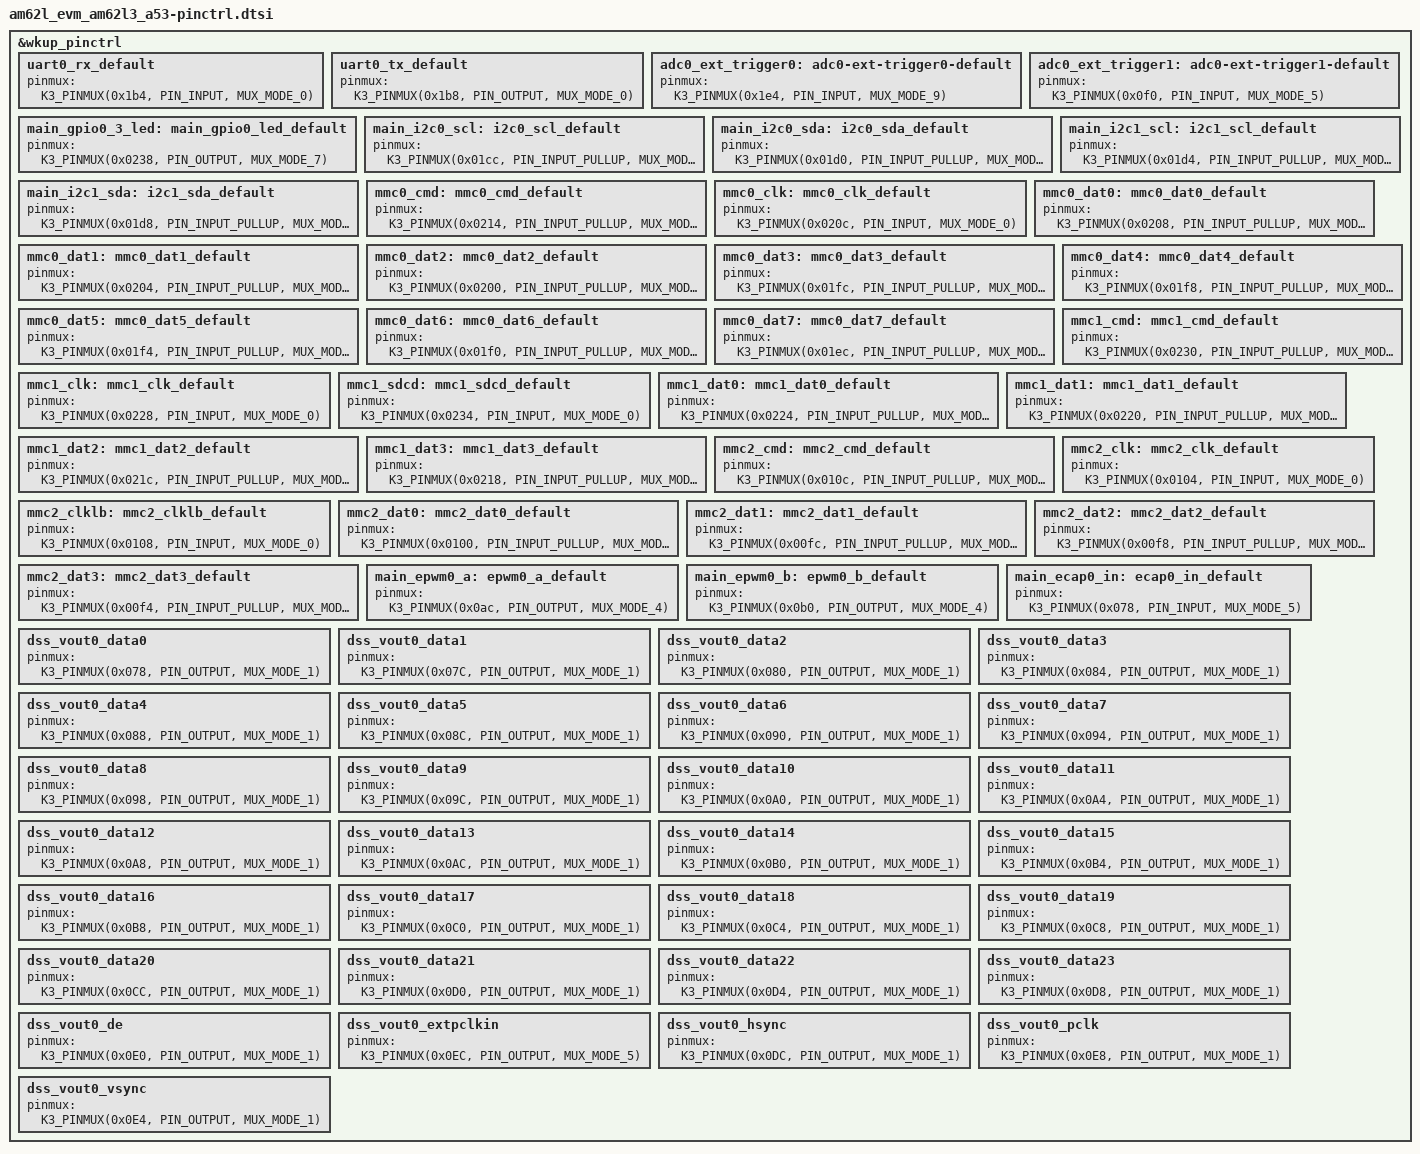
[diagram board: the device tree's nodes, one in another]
/*
 * Copyright (C) 2025 Texas Instruments Incorporated - https://www.ti.com/
 *
 * SPDX-License-Identifier: Apache-2.0
 */

&wkup_pinctrl {
	status = "okay";

	uart0_rx_default: uart0_rx_default {
		pinmux = <K3_PINMUX(0x1b4, PIN_INPUT, MUX_MODE_0)>; /* (D13) UART0_RXD */
	};

	uart0_tx_default: uart0_tx_default {
		pinmux = <K3_PINMUX(0x1b8, PIN_OUTPUT, MUX_MODE_0)>; /* (C13) UART0_TXD */
	};

	adc0_ext_trigger0: adc0-ext-trigger0-default {
		pinmux = <K3_PINMUX(0x1e4, PIN_INPUT, MUX_MODE_9)>; /* (D16) ADC_EXT_TRIGGER0 */
	};

	adc0_ext_trigger1: adc0-ext-trigger1-default {
		pinmux = <K3_PINMUX(0x0f0, PIN_INPUT, MUX_MODE_5)>; /* (M22) ADC_EXT_TRIGGER1 */
	};

	main_gpio0_3_led: main_gpio0_led_default {
		pinmux = <K3_PINMUX(0x0238, PIN_OUTPUT, MUX_MODE_7)>; /* (D6) MMC1_SDWP */
	};

	main_i2c0_scl: i2c0_scl_default {
		pinmux = <K3_PINMUX(0x01cc, PIN_INPUT_PULLUP, MUX_MODE_0)>; /* (B7) I2C0_SCL */
	};

	main_i2c0_sda: i2c0_sda_default {
		pinmux = <K3_PINMUX(0x01d0, PIN_INPUT_PULLUP, MUX_MODE_0)>; /* (A7) I2C0_SDA */
	};

	main_i2c1_scl: i2c1_scl_default {
		pinmux = <K3_PINMUX(0x01d4, PIN_INPUT_PULLUP, MUX_MODE_0)>; /* (D7) I2C1_SCL */
	};

	main_i2c1_sda: i2c1_sda_default {
		pinmux = <K3_PINMUX(0x01d8, PIN_INPUT_PULLUP, MUX_MODE_0)>; /* (A6) I2C1_SDA */
	};

	mmc0_cmd: mmc0_cmd_default {
		pinmux = <K3_PINMUX(0x0214, PIN_INPUT_PULLUP, MUX_MODE_0)>; /* (D2) MMC0_CMD */
	};

	mmc0_clk: mmc0_clk_default {
		pinmux = <K3_PINMUX(0x020c, PIN_INPUT, MUX_MODE_0)>; /* (B2) MMC0_CLK */
	};

	mmc0_dat0: mmc0_dat0_default {
		pinmux = <K3_PINMUX(0x0208, PIN_INPUT_PULLUP, MUX_MODE_0)>; /* (D3) MMC0_DAT0 */
	};

	mmc0_dat1: mmc0_dat1_default {
		pinmux = <K3_PINMUX(0x0204, PIN_INPUT_PULLUP, MUX_MODE_0)>; /* (D4) MMC0_DAT1 */
	};

	mmc0_dat2: mmc0_dat2_default {
		pinmux = <K3_PINMUX(0x0200, PIN_INPUT_PULLUP, MUX_MODE_0)>; /* (C1) MMC0_DAT2 */
	};

	mmc0_dat3: mmc0_dat3_default {
		pinmux = <K3_PINMUX(0x01fc, PIN_INPUT_PULLUP, MUX_MODE_0)>; /* (C2) MMC0_DAT3 */
	};

	mmc0_dat4: mmc0_dat4_default {
		pinmux = <K3_PINMUX(0x01f8, PIN_INPUT_PULLUP, MUX_MODE_0)>; /* (C4) MMC0_DAT4 */
	};

	mmc0_dat5: mmc0_dat5_default {
		pinmux = <K3_PINMUX(0x01f4, PIN_INPUT_PULLUP, MUX_MODE_0)>; /* (B3) MMC0_DAT5 */
	};

	mmc0_dat6: mmc0_dat6_default {
		pinmux = <K3_PINMUX(0x01f0, PIN_INPUT_PULLUP, MUX_MODE_0)>; /* (A3) MMC0_DAT6 */
	};

	mmc0_dat7: mmc0_dat7_default {
		pinmux = <K3_PINMUX(0x01ec, PIN_INPUT_PULLUP, MUX_MODE_0)>; /* (B4) MMC0_DAT7 */
	};

	mmc1_cmd: mmc1_cmd_default {
		pinmux = <K3_PINMUX(0x0230, PIN_INPUT_PULLUP, MUX_MODE_0)>; /* (Y3) MMC1_CMD */
	};

	mmc1_clk: mmc1_clk_default {
		pinmux = <K3_PINMUX(0x0228, PIN_INPUT, MUX_MODE_0)>; /* (Y2) MMC1_CLK */
	};

	mmc1_sdcd: mmc1_sdcd_default {
		pinmux = <K3_PINMUX(0x0234, PIN_INPUT, MUX_MODE_0)>; /* (B6) MMC1_SDCD */
	};

	mmc1_dat0: mmc1_dat0_default {
		pinmux = <K3_PINMUX(0x0224, PIN_INPUT_PULLUP, MUX_MODE_0)>; /* (AA1) MMC1_DAT0 */
	};

	mmc1_dat1: mmc1_dat1_default {
		pinmux = <K3_PINMUX(0x0220, PIN_INPUT_PULLUP, MUX_MODE_0)>; /* (Y4) MMC1_DAT1 */
	};

	mmc1_dat2: mmc1_dat2_default {
		pinmux = <K3_PINMUX(0x021c, PIN_INPUT_PULLUP, MUX_MODE_0)>; /* (AA2) MMC1_DAT2 */
	};

	mmc1_dat3: mmc1_dat3_default {
		pinmux = <K3_PINMUX(0x0218, PIN_INPUT_PULLUP, MUX_MODE_0)>; /* (AB2) MMC1_DAT3 */
	};

	mmc2_cmd: mmc2_cmd_default {
		pinmux = <K3_PINMUX(0x010c, PIN_INPUT_PULLUP, MUX_MODE_0)>; /* (U23) MMC2_CMD */
	};

	mmc2_clk: mmc2_clk_default {
		pinmux = <K3_PINMUX(0x0104, PIN_INPUT, MUX_MODE_0)>; /* (R23) MMC2_CLK */
	};

	mmc2_clklb: mmc2_clklb_default {
		pinmux = <K3_PINMUX(0x0108, PIN_INPUT, MUX_MODE_0)>; /* () MMC2_CLKLB */
	};

	mmc2_dat0: mmc2_dat0_default {
		pinmux = <K3_PINMUX(0x0100, PIN_INPUT_PULLUP, MUX_MODE_0)>; /* (U22) MMC2_DAT0 */
	};

	mmc2_dat1: mmc2_dat1_default {
		pinmux = <K3_PINMUX(0x00fc, PIN_INPUT_PULLUP, MUX_MODE_0)>; /* (T22) MMC2_DAT1 */
	};

	mmc2_dat2: mmc2_dat2_default {
		pinmux = <K3_PINMUX(0x00f8, PIN_INPUT_PULLUP, MUX_MODE_0)>; /* (T23) MMC2_DAT2 */
	};

	mmc2_dat3: mmc2_dat3_default {
		pinmux = <K3_PINMUX(0x00f4, PIN_INPUT_PULLUP, MUX_MODE_0)>; /* (R22) MMC2_DAT3 */
	};

	main_epwm0_a: epwm0_a_default {
		pinmux = <K3_PINMUX(0x0ac, PIN_OUTPUT, MUX_MODE_4)>; /* (G22) EHRPWM0_A */
	};

	main_epwm0_b: epwm0_b_default {
		pinmux = <K3_PINMUX(0x0b0, PIN_OUTPUT, MUX_MODE_4)>;  /* (F22) EHRPWM0_B */
	};

	main_ecap0_in: ecap0_in_default {
		pinmux = <K3_PINMUX(0x078, PIN_INPUT, MUX_MODE_5)>; /* (L22) ECAP0_IN_APWM_OUT */
	};

	dss_vout0_data0: dss_vout0_data0 {
		pinmux = <K3_PINMUX(0x078, PIN_OUTPUT, MUX_MODE_1)>; /* (L22) DSS_VOUT0_DATA0 */
	};

	dss_vout0_data1: dss_vout0_data1 {
		pinmux = <K3_PINMUX(0x07C, PIN_OUTPUT, MUX_MODE_1)>; /* (L23) DSS_VOUT0_DATA1 */
	};

	dss_vout0_data2: dss_vout0_data2 {
		pinmux = <K3_PINMUX(0x080, PIN_OUTPUT, MUX_MODE_1)>; /* (K22) DSS_VOUT0_DATA2 */
	};

	dss_vout0_data3: dss_vout0_data3 {
		pinmux = <K3_PINMUX(0x084, PIN_OUTPUT, MUX_MODE_1)>; /* (J23) DSS_VOUT0_DATA3 */
	};

	dss_vout0_data4: dss_vout0_data4 {
		pinmux = <K3_PINMUX(0x088, PIN_OUTPUT, MUX_MODE_1)>; /* (K23) DSS_VOUT0_DATA4 */
	};

	dss_vout0_data5: dss_vout0_data5 {
		pinmux = <K3_PINMUX(0x08C, PIN_OUTPUT, MUX_MODE_1)>; /* (H22) DSS_VOUT0_DATA5 */
	};

	dss_vout0_data6: dss_vout0_data6 {
		pinmux = <K3_PINMUX(0x090, PIN_OUTPUT, MUX_MODE_1)>; /* (H23) DSS_VOUT0_DATA6 */
	};

	dss_vout0_data7: dss_vout0_data7 {
		pinmux = <K3_PINMUX(0x094, PIN_OUTPUT, MUX_MODE_1)>; /* (J22) DSS_VOUT0_DATA7 */
	};

	dss_vout0_data8: dss_vout0_data8 {
		pinmux = <K3_PINMUX(0x098, PIN_OUTPUT, MUX_MODE_1)>; /* (H19) DSS_VOUT0_DATA8 */
	};

	dss_vout0_data9: dss_vout0_data9 {
		pinmux = <K3_PINMUX(0x09C, PIN_OUTPUT, MUX_MODE_1)>; /* (H20) DSS_VOUT0_DATA9 */
	};

	dss_vout0_data10: dss_vout0_data10 {
		pinmux = <K3_PINMUX(0x0A0, PIN_OUTPUT, MUX_MODE_1)>; /* (H21) DSS_VOUT0_DATA10 */
	};

	dss_vout0_data11: dss_vout0_data11 {
		pinmux = <K3_PINMUX(0x0A4, PIN_OUTPUT, MUX_MODE_1)>; /* (H18) DSS_VOUT0_DATA11 */
	};

	dss_vout0_data12: dss_vout0_data12 {
		pinmux = <K3_PINMUX(0x0A8, PIN_OUTPUT, MUX_MODE_1)>; /* (G23) DSS_VOUT0_DATA12 */
	};

	dss_vout0_data13: dss_vout0_data13 {
		pinmux = <K3_PINMUX(0x0AC, PIN_OUTPUT, MUX_MODE_1)>; /* (G22) DSS_VOUT0_DATA13 */
	};

	dss_vout0_data14: dss_vout0_data14 {
		pinmux = <K3_PINMUX(0x0B0, PIN_OUTPUT, MUX_MODE_1)>; /* (F22) DSS_VOUT0_DATA14 */
	};

	dss_vout0_data15: dss_vout0_data15 {
		pinmux = <K3_PINMUX(0x0B4, PIN_OUTPUT, MUX_MODE_1)>; /* (F23) DSS_VOUT0_DATA15 */
	};

	dss_vout0_data16: dss_vout0_data16 {
		pinmux = <K3_PINMUX(0x0B8, PIN_OUTPUT, MUX_MODE_1)>; /* (L21) DSS_VOUT0_DATA16 */
	};

	dss_vout0_data17: dss_vout0_data17 {
		pinmux = <K3_PINMUX(0x0C0, PIN_OUTPUT, MUX_MODE_1)>; /* (N19) DSS_VOUT0_DATA17 */
	};

	dss_vout0_data18: dss_vout0_data18 {
		pinmux = <K3_PINMUX(0x0C4, PIN_OUTPUT, MUX_MODE_1)>; /* (N20) DSS_VOUT0_DATA18 */
	};

	dss_vout0_data19: dss_vout0_data19 {
		pinmux = <K3_PINMUX(0x0C8, PIN_OUTPUT, MUX_MODE_1)>; /* (M19) DSS_VOUT0_DATA19 */
	};

	dss_vout0_data20: dss_vout0_data20 {
		pinmux = <K3_PINMUX(0x0CC, PIN_OUTPUT, MUX_MODE_1)>; /* (P23) DSS_VOUT0_DATA20 */
	};

	dss_vout0_data21: dss_vout0_data21 {
		pinmux = <K3_PINMUX(0x0D0, PIN_OUTPUT, MUX_MODE_1)>; /* (P22) DSS_VOUT0_DATA21 */
	};

	dss_vout0_data22: dss_vout0_data22 {
		pinmux = <K3_PINMUX(0x0D4, PIN_OUTPUT, MUX_MODE_1)>; /* (N23) DSS_VOUT0_DATA22 */
	};

	dss_vout0_data23: dss_vout0_data23 {
		pinmux = <K3_PINMUX(0x0D8, PIN_OUTPUT, MUX_MODE_1)>; /* (N22) DSS_VOUT0_DATA23 */
	};

	dss_vout0_de: dss_vout0_de {
		pinmux = <K3_PINMUX(0x0E0, PIN_OUTPUT, MUX_MODE_1)>; /* (M21) DSS_VOUT0_DE */
	};

	dss_vout0_extpclkin: dss_vout0_extpclkin {
		pinmux = <K3_PINMUX(0x0EC, PIN_OUTPUT, MUX_MODE_5)>; /* (M23) DSS_VOUT0_EXTPCLKIN */
	};

	dss_vout0_hsync: dss_vout0_hsync {
		pinmux = <K3_PINMUX(0x0DC, PIN_OUTPUT, MUX_MODE_1)>; /* (N21) DSS_VOUT0_HSYNC */
	};

	dss_vout0_pclk: dss_vout0_pclk {
		pinmux = <K3_PINMUX(0x0E8, PIN_OUTPUT, MUX_MODE_1)>; /* (L19) DSS_VOUT0_PCLK */
	};

	dss_vout0_vsync: dss_vout0_vsync {
		pinmux = <K3_PINMUX(0x0E4, PIN_OUTPUT, MUX_MODE_1)>; /* (L20) DSS_VOUT0_VSYNC */
	};
};
